# STM32U575 register map
File version: 1.4
CPU: CM33 r0p1, little endian, MPU, FPU, 4 interrupt priority bits
Registers are 32-bit, read-write, reset 0x0 unless marked. A register's access mark holds for its fields unless they carry their own. Offsets are from the block's base; [hi:lo] are bit positions; lines under a group give offsets from that group; {n}, {i} and the like mark numbered series; 'fields as' and 'values as' point back to an identical list.

## ADC1
Base 0x42028000
Same registers: SEC_ADC1 0x52028000
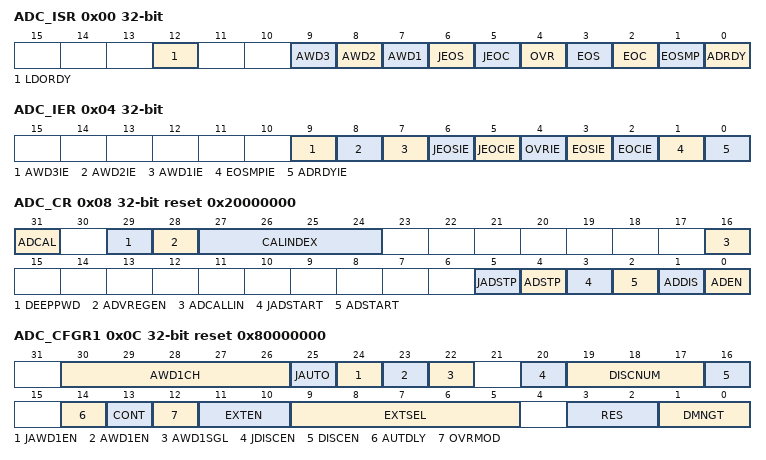
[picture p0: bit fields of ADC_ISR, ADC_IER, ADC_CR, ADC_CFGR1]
0x00 ADC_ISR access per field — ADC interrupt and status register
  [12] LDORDY ro — ADC voltage regulator ready This bit is set by hardware. It indicates that the ADC internal supply is ready. The ADC is available after tADCVREG_SETUP time.
    0=ADC voltage regulator disabled; 1=ADC voltage regulator enabled
  [9] AWD3 rw — Analog watchdog 3 flag This bit is set by hardware when the converted voltage crosses the values programmed in the fields LT3[7:0] and HT3[7:0] of ADC_LTR3 & ADC_HTR3 register. It is cleared by software writing 1 to it.
    0=No analog watchdog 3 event occurred (or the flag event was already acknowledged and cleared by software); 1=Analog watchdog 3 event occurred
  [8] AWD2 rw — Analog watchdog 2 flag This bit is set by hardware when the converted voltage crosses the values programmed in the fields LT2[7:0] and HT2[7:0] of ADC_LTR2 & ADC_HTR2 register. It is cleared by software writing 1 to it.
    0=No analog watchdog 2 event occurred (or the flag event was already acknowledged and cleared by software); 1=Analog watchdog 2 event occurred
  [7] AWD1 rw — Analog watchdog 1 flag This bit is set by hardware when the converted voltage crosses the values programmed in the fields LT1[11:0] and HT1[11:0] of ADC_LTR1, & ADC_HTR1 register. It is cleared by software. writing 1 to it.
    0=No analog watchdog 1 event occurred (or the flag event was already acknowledged and cleared by software); 1=Analog watchdog 1 event occurred
  [6] JEOS rw — Injected channel end of sequence flag This bit is set by hardware at the end of the conversions of all injected channels in the group. It is cleared by software writing 1 to it.
    0=Injected conversion sequence not complete (or the flag event was already acknowledged and cleared by software); 1=Injected conversions complete
  [5] JEOC rw — Injected channel end of conversion flag This bit is set by hardware at the end of each injected conversion of a channel when a new data is available in the corresponding ADC_JDRy register. It is cleared by software writing 1 to it or by reading the corresponding ADC_JDRy register
    0=Injected channel conversion not complete (or the flag event was already acknowledged and cleared by software); 1=Injected channel conversion complete
  [4] OVR rw — ADC overrun This bit is set by hardware when an overrun occurs on a regular channel, meaning that a new conversion has completed while the EOC flag was already set. It is cleared by software writing 1 to it.
    0=No overrun occurred (or the flag event was already acknowledged and cleared by software); 1=Overrun has occurred
  [3] EOS rw — End of regular sequence flag This bit is set by hardware at the end of the conversions of a regular sequence of channels. It is cleared by software writing 1 to it.
    0=Regular Conversions sequence not complete (or the flag event was already acknowledged and cleared by software); 1=Regular Conversions sequence complete
  [2] EOC rw — End of conversion flag This bit is set by hardware at the end of each regular conversion of a channel when a new data is available in the ADC_DR register. It is cleared by software writing 1 to it or by reading the ADC_DR register
    0=Regular channel conversion not complete (or the flag event was already acknowledged and cleared by software); 1=Regular channel conversion complete
  [1] EOSMP rw — End of sampling flag This bit is set by hardware during the conversion of any channel (only for regular channels), at the end of the sampling phase.
    0=not at the end of the sampling phase (or the flag event was already acknowledged and cleared by software); 1=End of sampling phase reached
  [0] ADRDY rw — ADC ready This bit is set by hardware after the ADC has been enabled (bit ADEN = 1) and when the ADC reaches a state where it is ready to accept conversion requests. It is cleared by software writing 1 to it.
    0=ADC not yet ready to start conversion (or the flag event was already acknowledged and cleared by software); 1=ADC is ready to start conversion
0x04 ADC_IER — ADC interrupt enable register
  [9] AWD3IE — Analog watchdog 3 interrupt enable This bit is set and cleared by software to enable/disable the analog watchdog 2 interrupt. Note: Software is allowed to write this bit only when ADSTART = 0 and JADSTART = 0 (which ensures that no conversion is ongoing).
    0=Analog watchdog 3 interrupt disabled; 1=Analog watchdog 3 interrupt enabled
  [8] AWD2IE — Analog watchdog 2 interrupt enable This bit is set and cleared by software to enable/disable the analog watchdog 2 interrupt. Note: Software is allowed to write this bit only when ADSTART = 0 and JADSTART = 0 (which ensures that no conversion is ongoing).
    0=Analog watchdog 2 interrupt disabled; 1=Analog watchdog 2 interrupt enabled
  [7] AWD1IE — Analog watchdog 1 interrupt enable This bit is set and cleared by software to enable/disable the analog watchdog 1 interrupt. Note: Software is allowed to write this bit only when ADSTART = 0 and JADSTART = 0 (which ensures that no conversion is ongoing).
    0=Analog watchdog 1 interrupt disabled; 1=Analog watchdog 1 interrupt enabled
  [6] JEOSIE — End of injected sequence of conversions interrupt enable This bit is set and cleared by software to enable/disable the end of injected sequence of conversions interrupt. Note: Software is allowed to write this bit only when JADSTART = 0 (which ensures that no injected conversion is ongoing).
    0=JEOS interrupt disabled; 1=JEOS interrupt enabled. An interrupt is generated when the JEOS bit is set.
  [5] JEOCIE — End of injected conversion interrupt enable This bit is set and cleared by software to enable/disable the end of an injected conversion interrupt. Note: Software is allowed to write this bit only when JADSTART = 0 (which ensures that no regular conversion is ongoing).
    0=JEOC interrupt disabled; 1=JEOC interrupt enabled. An interrupt is generated when the JEOC bit is set.
  [4] OVRIE — Overrun interrupt enable This bit is set and cleared by software to enable/disable the Overrun interrupt of a regular conversion. Note: Software is allowed to write this bit only when ADSTART = 0 (which ensures that no regular conversion is ongoing).
    0=Overrun interrupt disabled; 1=Overrun interrupt enabled. An interrupt is generated when the OVR bit is set.
  [3] EOSIE — End of regular sequence of conversions interrupt enable This bit is set and cleared by software to enable/disable the end of regular sequence of conversions interrupt. Note: Software is allowed to write this bit only when ADSTART = 0 (which ensures that no regular conversion is ongoing).
    0=EOS interrupt disabled; 1=EOS interrupt enabled. An interrupt is generated when the EOS bit is set.
  [2] EOCIE — End of regular conversion interrupt enable This bit is set and cleared by software to enable/disable the end of a regular conversion interrupt. Note: Software is allowed to write this bit only when ADSTART = 0 (which ensures that no regular conversion is ongoing).
    0=EOC interrupt disabled; 1=EOC interrupt enabled. An interrupt is generated when the EOC bit is set.
  [1] EOSMPIE — End of sampling flag interrupt enable for regular conversions This bit is set and cleared by software to enable/disable the end of the sampling phase interrupt for regular conversions. Note: Software is allowed to write this bit only when ADSTART = 0 (which ensures that no regular conversion is ongoing).
    0=EOSMP interrupt disabled; 1=EOSMP interrupt enabled. An interrupt is generated when the EOSMP bit is set.
  [0] ADRDYIE — ADC ready interrupt enable This bit is set and cleared by software to enable/disable the ADC Ready interrupt. Note: Software is allowed to write this bit only when ADSTART = 0 and JADSTART = 0 (which ensures that no conversion is ongoing).
    0=ADRDY interrupt disabled; 1=ADRDY interrupt enabled. An interrupt is generated when the ADRDY bit is set.
0x08 ADC_CR reset 0x20000000 — ADC control register
  [31] ADCAL — ADC calibration This bit is set by software to start the ADC calibration. It is cleared by hardware after calibration is complete. Note: The software is allowed to launch a calibration by setting ADCAL only when ADEN = 0.
    0=Calibration complete; 1=Write 1 to calibrate the ADC. Read at 1 means that a calibration in progress.
  [29] DEEPPWD — Deep-power-down enable This bit is set and cleared by software to put the ADC in Deep-power-down mode. Note: The software is allowed to write this bit only when the ADC is disabled (ADCAL = 0, JADSTART = 0, JADSTP = 0, ADSTART = 0, ADSTP = 0, ADDIS = 0 and ADEN = 0).
    0=ADC not in deep-power down; 1=ADC in Deep-power-down (default reset state)
  [28] ADVREGEN — ADC voltage regulator enable This bits is set by software to enable the ADC voltage regulator. Before performing any operation such as launching a calibration or enabling the ADC, the ADC voltage regulator must first be enabled and the software must wait for the regulator start-up time. For more details about the ADC voltage regulator enable and disable sequences, refer to (ADVREGEN). The software can program this bit field only when the ADC is disabled (ADCAL = 0, JADSTART = 0, ADSTART = 0, ADSTP = 0, ADDIS = 0 and ADEN = 0).
    0=ADC Voltage regulator disabled; 1=ADC Voltage regulator enabled
  [27:24] CALINDEX — Calibration factor This bitfield controls the calibration factor to be read or written. Calibration index 0 is dedicated to single-ended and differential offsets, calibration index 1 to 7 to the linearity calibration factors, and index 8 to the internal offset: Others: Reserved, must not be used Note: ADC_CALFACT2[31:0] correspond to the location of CALINDEX[3:0] calibration factor data (see for details).
    0=Offset calibration factor; {v}=linearity calibration factor {v} (v=1..6); 7=linearity calibration factor 7 and internal offset (write access only); 8=internal offset (read access only)
  [16] ADCALLIN — Linearity calibration This bit is set and cleared by software to enable the linearity calibration. Note: The software is allowed to write this bit only when the ADC is disabled and is not calibrating (ADCAL = 0, JADSTART = 0, JADSTP = 0, ADSTART = 0, ADSTP = 0, ADDIS = 0 and ADEN = 0).
    0=Writing ADCAL launches a calibration without the linearity calibration; 1=Writing ADCAL launches a calibration with he linearity calibration
  [5] JADSTP — ADC stop of injected conversion command This bit is set by software to stop and discard an ongoing injected conversion (JADSTP Command). It is cleared by hardware when the conversion is effectively discarded and the ADC injected sequence and triggers can be re-configured. The ADC is then ready to accept a new start of injected conversions (JADSTART command). Note: The software is allowed to set JADSTP only when JADSTART = 1 and ADDIS = 0 (ADC is enabled and eventually converting an injected conversion and there is no pending request to disable the ADC). In Auto-injection mode (JAUTO = 1), setting ADSTP bit aborts both regular and injected conversions (do not use JADSTP)
    0=No ADC stop injected conversion command ongoing; 1=Write 1 to stop injected conversions ongoing. Read 1 means that an ADSTP command is in progress.
  [4] ADSTP — ADC stop of regular conversion command This bit is set by software to stop and discard an ongoing regular conversion (ADSTP Command). It is cleared by hardware when the conversion is effectively discarded and the ADC regular sequence and triggers can be re-configured. The ADC is then ready to accept a new start of regular conversions (ADSTART command). Note: The software is allowed to set ADSTP only when ADSTART = 1 and ADDIS = 0 (ADC is enabled and eventually converting a regular conversion and there is no pending request to disable the ADC). In Auto-injection mode (JAUTO = 1), setting ADSTP bit aborts both regular and injected conversions (do not use JADSTP).
    0=No ADC stop regular conversion command ongoing; 1=Write 1 to stop regular conversions ongoing. Read 1 means that an ADSTP command is in progress.
  [3] JADSTART — ADC start of injected conversion This bit is set by software to start ADC conversion of injected channels. Depending on the configuration bits JEXTEN[1:0], a conversion starts immediately (software trigger configuration) or once an injected hardware trigger event occurs (hardware trigger configuration). It is cleared by hardware: in Single conversion mode when software trigger is selected (JEXTSEL = 0x0): at the assertion of the end of injected conversion sequence (JEOS) flag. in all cases: after the execution of the JADSTP command, at the same time as JADSTP is cleared by hardware. Note: The software is allowed to set JADSTART only when ADEN = 1 and ADDIS = 0 (ADC is enabled and there is no pending request to disable the ADC). In Auto-injection mode (JAUTO = 1), regular and auto-injected conversions are started by setting bit ADSTART (JADSTART must be kept cleared)
    0=No ADC injected conversion is ongoing; 1=Write 1 to start injected conversions. Read 1 means that the ADC is operating and eventually converting an injected channel.
  [2] ADSTART — ADC start of regular conversion This bit is set by software to start ADC conversion of regular channels. Depending on the configuration bits EXTEN[1:0], a conversion starts immediately (software trigger configuration) or once a regular hardware trigger event occurs (hardware trigger configuration). It is cleared by hardware: in Single conversion mode (CONT = 0, DISCEN = 0) when software trigger is selected (EXTEN[1:0] = 0x0): at the assertion of the end of regular conversion sequence (EOS) flag. In Discontinuous conversion mode (CONT = 0, DISCEN = 1), when the software trigger is selected (EXTEN[1:0] = 0x0): at the end of conversion (EOC) flag. in all other cases: after the execution of the ADSTP command, at the same time that ADSTP is cleared by hardware. Note: The software is allowed to set ADSTART only when ADEN = 1 and ADDIS = 0 (ADC is enabled and there is no pending request to disable the ADC) In Auto-injection mode (JAUTO = 1), regular and auto-injected conversions are started by setting bit ADSTART (JADSTART must be kept cleared)
    0=No ADC regular conversion is ongoing; 1=Write 1 to start regular conversions. Read 1 means that the ADC is operating and eventually converting a regular channel.
  [1] ADDIS — ADC disable command This bit is set by software to disable the ADC (ADDIS command) and put it into power-down state (OFF state). It is cleared by hardware once the ADC is effectively disabled (ADEN is also cleared by hardware at this time). Note: The software is allowed to set ADDIS only when ADEN = 1 and both ADSTART = 0 and JADSTART = 0 (which ensures that no conversion is ongoing)
    0=no ADDIS command ongoing; 1=Write 1 to disable the ADC. Read 1 means that an ADDIS command is in progress.
  [0] ADEN — ADC enable control This bit is set by software to enable the ADC. The ADC is effectively ready to operate once the flag ADRDY has been set. It is cleared by hardware when the ADC is disabled, after the execution of the ADDIS command. Note: The software is allowed to set ADEN only when all bits of ADC_CR registers are 0 (ADCAL = 0, JADSTART = 0, ADSTART = 0, ADSTP = 0, ADDIS = 0 and ADEN = 0) except for bit ADVREGEN which must be 1 (and the software must have wait for the startup time of the voltage regulator)
    0=ADC is disabled (OFF state); 1=Write 1 to enable the ADC
0x0C ADC_CFGR1 reset 0x80000000 — ADC configuration register
  [30:26] AWD1CH — Analog watchdog 1 channel selection These bits are set and cleared by software. They select the input channel to be guarded by the analog watchdog. ..... Others: Reserved, must not be used Note: The channel selected by AWD1CH must be also selected into the SQRi or JSQRi registers. Software is allowed to write these bits only when ADSTART = 0 and JADSTART = 0 (which ensures that no conversion is ongoing).
    0=ADC analog input channel-0 monitored by AWD1; 1=ADC analog input channel-1 monitored by AWD1; 19=ADC analog input channel-19 monitored by AWD1
  [25] JAUTO — Automatic injected group conversion This bit is set and cleared by software to enable/disable automatic injected group conversion after regular group conversion. Note: The software is allowed to write this bit only when ADSTART = 0 and JADSTART = 0 (which ensures that no regular nor injected conversion is ongoing).
    0=Automatic injected group conversion disabled; 1=Automatic injected group conversion enabled
  [24] JAWD1EN — Analog watchdog 1 enable on injected channels This bit is set and cleared by software Note: The software is allowed to write this bit only when JADSTART = 0 (which ensures that no injected conversion is ongoing).
    0=Analog watchdog 1 disabled on injected channels; 1=Analog watchdog 1 enabled on injected channels
  [23] AWD1EN — Analog watchdog 1 enable on regular channels This bit is set and cleared by software Note: The software is allowed to write this bit only when ADSTART = 0 (which ensures that no regular conversion is ongoing).
    0=Analog watchdog 1 disabled on regular channels; 1=Analog watchdog 1 enabled on regular channels
  [22] AWD1SGL — Enable the watchdog 1 on a single channel or on all channels This bit is set and cleared by software to enable the analog watchdog on the channel identified by the AWD1CH[4:0] bits or on all the channels Note: The software is allowed to write these bits only when ADSTART = 0 and JADSTART = 0 (which ensures that no conversion is ongoing).
    0=Analog watchdog 1 enabled on all channels; 1=Analog watchdog 1 enabled on a single channel
  [20] JDISCEN — Discontinuous mode on injected channels This bit is set and cleared by software to enable/disable discontinuous mode on the injected channels of a group. Note: The software is allowed to write this bit only when JADSTART = 0 (which ensures that no injected conversion is ongoing). It is not possible to use both auto-injected mode and discontinuous mode simultaneously: the bits DISCEN and JDISCEN must be kept cleared by software when JAUTO is set.
    0=Discontinuous mode on injected channels disabled; 1=Discontinuous mode on injected channels enabled
  [19:17] DISCNUM — Discontinuous mode channel count These bits are written by software to define the number of regular channels to be converted in discontinuous mode, after receiving an external trigger. ... Note: The software is allowed to write these bits only when ADSTART = 0 (which ensures that no regular conversion is ongoing).
    0=1 channel; 1=2 channels; 7=8 channels
  [16] DISCEN — Discontinuous mode for regular channels This bit is set and cleared by software to enable/disable Discontinuous mode for regular channels. Note: It is not possible to have both discontinuous mode and continuous mode enabled: it is forbidden to set both DISCEN = 1 and CONT = 1. It is not possible to use both auto-injected mode and discontinuous mode simultaneously: the bits DISCEN and JDISCEN must be kept cleared by software when JAUTO is set. The software is allowed to write this bit only when ADSTART = 0 (which ensures that no regular conversion is ongoing).
    0=Discontinuous mode for regular channels disabled; 1=Discontinuous mode for regular channels enabled
  [14] AUTDLY — Delayed conversion mode This bit is set and cleared by software to enable/disable the Auto Delayed Conversion mode.. Note: The software is allowed to write this bit only when ADSTART = 0 and JADSTART = 0 (which ensures that no conversion is ongoing).
    0=Auto-delayed conversion mode off; 1=Auto-delayed conversion mode on
  [13] CONT — Single / continuous conversion mode for regular conversions This bit is set and cleared by software. If it is set, regular conversion takes place continuously until it is cleared. Note: It is not possible to have both discontinuous mode and continuous mode enabled: it is forbidden to set both DISCEN = 1 and CONT = 1. The software is allowed to write this bit only when ADSTART = 0 (which ensures that no regular conversion is ongoing).
    0=Single conversion mode; 1=Continuous conversion mode
  [12] OVRMOD — Overrun Mode This bit is set and cleared by software and configure the way data overrun is managed. Note: The software is allowed to write this bit only when ADSTART = 0 (which ensures that no regular conversion is ongoing).
    0=ADC_DR register is preserved with the old data when an overrun is detected; 1=ADC_DR register is overwritten with the last conversion result when an overrun is detected
  [11:10] EXTEN — External trigger enable and polarity selection for regular channels These bits are set and cleared by software to select the external trigger polarity and enable the trigger of a regular group. Note: The software is allowed to write these bits only when ADSTART = 0 (which ensures that no regular conversion is ongoing).
    0=Hardware trigger detection disabled (conversions can be launched by software); 1=Hardware trigger detection on the rising edge; 2=Hardware trigger detection on the falling edge; 3=Hardware trigger detection on both the rising and falling edges
  [9:5] EXTSEL — External trigger selection for regular group These bits select the external event used to trigger the start of conversion of a regular group: ... Refer to the ADC external trigger for regular channels in signals for details on trigger mapping. Note: The software is allowed to write these bits only when ADSTART = 0 (which ensures that no regular conversion is ongoing).
    0=adc_ext_trg0; 1=adc_ext_trg1
  [3:2] RES — Data resolution These bits are written by software to select the resolution of the conversion. Note: The software is allowed to write these bits only when ADSTART = 0 and JADSTART = 0 (which ensures that no conversion is ongoing).
    0=14 bits; 1=12 bits; 2=10 bits; 3=8bits
  [1:0] DMNGT — Data management configuration This bit is set and cleared by software to select how the ADC interface output data are managed. Note: The software is allowed to write this bit only when ADSTART = 0 and JADSTART = 0 (which ensures that no conversion is ongoing).
    0=Regular conversion data stored in DR only; 1=DMA One -shot mode selected; 2=MDF mode selected; 3=DMA Circular mode selected
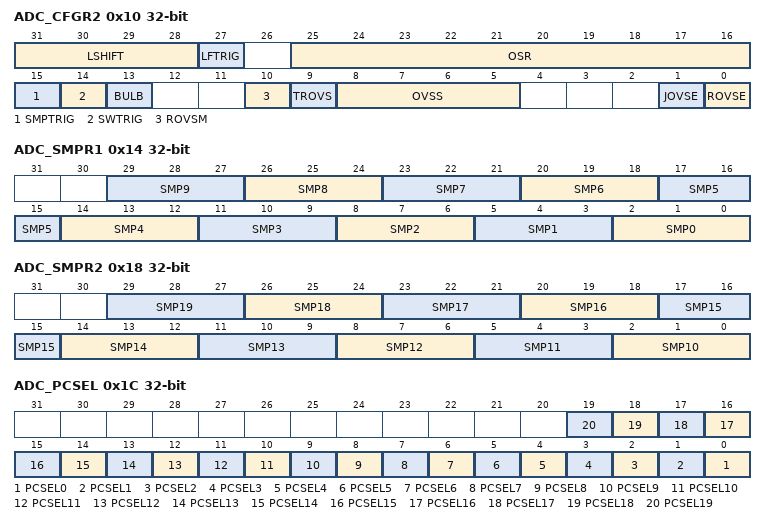
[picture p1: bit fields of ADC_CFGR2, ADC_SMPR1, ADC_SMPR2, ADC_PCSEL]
0x10 ADC_CFGR2 — ADC configuration register 2
  [31:28] LSHIFT — Left shift factor This bitfield is set and cleared by software to define the left shifting applied to the final result with or without oversampling. Note: The software is allowed to write this bit only when ADSTART = 0 (which ensures that no conversion is ongoing).
    0=No left shift; {v}={v}-bit left shift (v=1..15)
  [27] LFTRIG — Low-frequency trigger This bit is set and cleared by software Note: The software is allowed to write this bit only when ADSTART = 0 (which ensures that no conversion is ongoing).
    0=Low-frequency trigger mode disabled; 1=Low-frequency trigger mode enabled
  [25:16] OSR — Oversampling ratio This bitfield is set and cleared by software to define the oversampling ratio. 2: 3x ... 1023: 1024x Note: The software is allowed to write this bit only when ADSTART = 0 (which ensures that no conversion is ongoing).
    0=1x (no oversampling); 1=2x
  [15] SMPTRIG — Sampling time control trigger mode This bit is set and cleared by software to enable the sampling time control trigger mode. The sampling time starts on the trigger rising edge, and the conversion on the trigger falling edge. EXTEN[1:0] bits must be set to 01. BULB bit must not be set when the SMPTRIG bit is set. When EXTEN[1:0] bits is set to 00, set SWTRIG to start the sampling and clear SWTRIG bit to start the conversion. Note: The software is allowed to write this bit only when ADSTART = 0 (which ensures that no conversion is ongoing).
    0=Sampling time control trigger mode disabled; 1=Sampling time control trigger mode enabled
  [14] SWTRIG — Software trigger bit for sampling time control trigger mode This bit is set and cleared by software to enable the bulb sampling mode. Note: The software is allowed to write this bit only when ADSTART = 0 (which ensures that no conversion is ongoing).
    0=Software trigger starts the conversion for sampling time control trigger mode; 1=Software trigger starts the sampling for sampling time control trigger mode
  [13] BULB — Bulb sampling mode This bit is set and cleared by software to select the bulb sampling mode. SMPTRIG bit must not be set when the BULB bit is set. The very first ADC conversion is performed with the sampling time specified in SMPx bits. Note: The software is allowed to write this bit only when ADSTART = 0 (which ensures that no conversion is ongoing).
    0=Bulb sampling mode disabled; 1=Bulb sampling mode enabled. The sampling period starts just after the previous end of the conversion.
  [10] ROVSM — Regular Oversampling mode This bit is set and cleared by software to select the regular oversampling mode. Note: The software is allowed to write this bit only when ADSTART = 0 (which ensures that no conversion is ongoing).
    0=Continued mode: When injected conversions are triggered, the oversampling is temporary stopped and continued after the injection sequence (oversampling buffer is maintained during injected sequence); 1=Resumed mode: When injected conversions are triggered, the current oversampling is aborted and resumed from start after the injection sequence (oversampling buffer is zeroed by injected sequence start)
  [9] TROVS — Triggered Regular Oversampling This bit is set and cleared by software to enable triggered oversampling Note: The software is allowed to write this bit only when ADSTART = 0 (which ensures that no conversion is ongoing).
    0=All oversampled conversions for a channel are done consecutively following a trigger; 1=Each oversampled conversion for a channel needs a new trigger
  [8:5] OVSS — Oversampling right shift This bit field is set and cleared by software to define the right shifting applied to the raw oversampling result. Others: Reserved, must not be used. Note: The software is allowed to write these bits only when ADSTART = 0 (which ensures that no conversion is ongoing).
    0=No right shift; {v}={v}-bit right shift (v=1..11)
  [1] JOVSE — Injected Oversampling Enable This bit is set and cleared by software to enable injected oversampling. Note: The software is allowed to write this bit only when ADSTART = 0 and JADSTART = 0 (which ensures that no conversion is ongoing)
    0=Injected oversampling disabled; 1=Injected oversampling enabled
  [0] ROVSE — Regular Oversampling Enable This bit is set and cleared by software to enable regular oversampling. Note: The software is allowed to write this bit only when ADSTART = 0 and JADSTART = 0 (which ensures that no conversion is ongoing)
    0=Regular Oversampling disabled; 1=Regular Oversampling enabled
0x14 ADC_SMPR1 — ADC sample time register 1
  [all] fields
    0=5 ADC clock cycles; 1=6 ADC clock cycles; 2=12 ADC clock cycles; 3=20 ADC clock cycles; 4=36 ADC clock cycles; 5=68 ADC clock cycles; 6=391 ADC clock cycles; 7=814 ADC clock cycles
  [3n+2:3n] SMP{n} (n=0..9) — Channel x sampling time selection (x = 0 to 9) These bits are written by software to select the sampling time individually for each channel. During sample cycles, the channel selection bits must remain unchanged. Note: The software is allowed to write these bits only when ADSTART = 0 and JADSTART = 0 (which ensures that no conversion is ongoing).
0x18 ADC_SMPR2 — ADC sample time register 2
  [all] fields
    values as the fields of ADC_SMPR1
  [3n-28:3n-30] SMP{n} (n=10..19) — Channel x sampling time selection (x = 0 to 9) These bits are written by software to select the sampling time individually for each channel. During sampling cycles, the channel selection bits must remain unchanged. Note: The software is allowed to write these bits only when ADSTART = 0 and JADSTART = 0 (which ensures that no conversion is ongoing).
0x1C ADC_PCSEL — ADC channel preselection register
  [all] fields
    0=Input channel i (VINP[i]) is not preselected for conversion, the ADC conversion of this channel shows a wrong result; 1=Input channel i (VINP[i]) is preselected for conversion
  [n] PCSEL{n} (n=0..19) — Channel i (VINP[i]) preselection These bits are written by software to preselect the input channel I/O instance to be converted. Note: The software is allowed to write these bits only when ADSTART = 0 and JADSTART = 0 (which ensures that no conversion is ongoing).
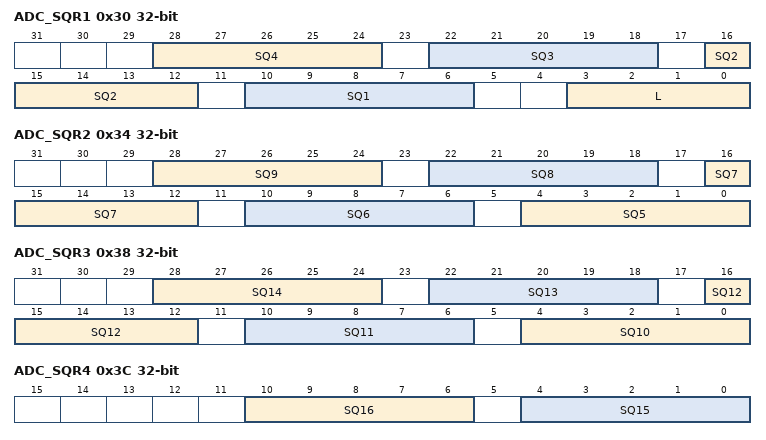
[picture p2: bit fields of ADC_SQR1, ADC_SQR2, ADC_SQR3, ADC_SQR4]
0x30 ADC_SQR1 — ADC regular sequence register 1
  [28:24] SQ4 — 4th conversion in regular sequence These bits are written by software with the channel number (0..19) assigned as the 4th in the regular conversion sequence.
  [22:18] SQ3 — 3rd conversion in regular sequence These bits are written by software with the channel number (0..19) assigned as the 3rd in the regular conversion sequence. Note: The software is allowed to write these bits only when ADSTART = 0 (which ensures that no regular conversion is ongoing).
  [16:12] SQ2 — 2nd conversion in regular sequence These bits are written by software with the channel number (0..19) assigned as the 2nd in the regular conversion sequence. Note: The software is allowed to write these bits only when ADSTART = 0 (which ensures that no regular conversion is ongoing).
  [10:6] SQ1 — 1st conversion in regular sequence These bits are written by software with the channel number (0..19) assigned as the 1st in the regular conversion sequence. Note: The software is allowed to write these bits only when ADSTART = 0 (which ensures that no regular conversion is ongoing).
  [3:0] L — Regular channel sequence length These bits are written by software to define the total number of conversions in the regular channel conversion sequence. ... Note: The software is allowed to write these bits only when ADSTART = 0 (which ensures that no regular conversion is ongoing).
    0=1 conversion; 1=2 conversions; 15=16 conversions
0x34 ADC_SQR2 — ADC regular sequence register 2
  [28:24] SQ9 — 9th conversion in regular sequence These bits are written by software with the channel number (0..19) assigned as the 9th in the regular conversion sequence. Note: The software is allowed to write these bits only when ADSTART = 0 (which ensures that no regular conversion is ongoing).
  [22:18] SQ8 — 8th conversion in regular sequence These bits are written by software with the channel number (0..19) assigned as the 8th in the regular conversion sequence Note: The software is allowed to write these bits only when ADSTART = 0 (which ensures that no regular conversion is ongoing).
  [16:12] SQ7 — 7th conversion in regular sequence These bits are written by software with the channel number (0..19) assigned as the 7th in the regular conversion sequence. Note: The software is allowed to write these bits only when ADSTART = 0 (which ensures that no regular conversion is ongoing).
  [10:6] SQ6 — 6th conversion in regular sequence These bits are written by software with the channel number (0..19) assigned as the 6th in the regular conversion sequence. Note: The software is allowed to write these bits only when ADSTART = 0 (which ensures that no regular conversion is ongoing).
  [4:0] SQ5 — 5th conversion in regular sequence These bits are written by software with the channel number (0..19) assigned as the 5th in the regular conversion sequence. Note: The software is allowed to write these bits only when ADSTART = 0 (which ensures that no regular conversion is ongoing).
0x38 ADC_SQR3 — ADC regular sequence register 3
  [6n-56:6n-60] SQ{n} (n=10..14) — {n}th conversion in regular sequence These bits are written by software with the channel number (0..19) assigned as the {n}th in the regular conversion sequence. Note: The software is allowed to write these bits only when ADSTART = 0 (which ensures that no regular conversion is ongoing).
0x3C ADC_SQR4 — ADC regular sequence register 4
  [10:6] SQ16 — 16th conversion in regular sequence These bits are written by software with the channel number (0..19) assigned as the 16th in the regular conversion sequence. Note: The software is allowed to write these bits only when ADSTART = 0 (which ensures that no regular conversion is ongoing).
  [4:0] SQ15 — 15th conversion in regular sequence These bits are written by software with the channel number (0..19) assigned as the 15th in the regular conversion sequence. Note: The software is allowed to write these bits only when ADSTART = 0 (which ensures that no regular conversion is ongoing).
0x40 ADC_DR ro — ADC regular Data Register
  [31:0] RDATA — Regular data converted These bits are read-only. They contain the conversion result from the last converted regular channel. The data are left- or right-aligned as described in .
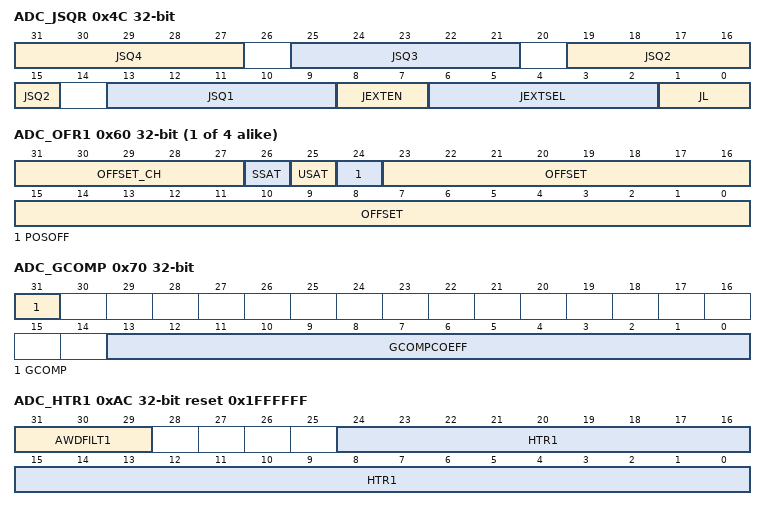
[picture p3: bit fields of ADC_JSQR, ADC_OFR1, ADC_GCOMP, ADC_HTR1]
0x4C ADC_JSQR — ADC injected sequence register
  [31:27] JSQ4 — 4th conversion in the injected sequence These bits are written by software with the channel number (0..19) assigned as the 4th in the injected conversion sequence. Note: The software is allowed to write these bits only when JADSTART = 0 (which ensures that no injected conversion is ongoing.
  [25:21] JSQ3 — 3rd conversion in the injected sequence These bits are written by software with the channel number (0..19) assigned as the 3rd in the injected conversion sequence. Note: The software is allowed to write these bits only when JADSTART = 0 (which ensures that no injected conversion is ongoing.
  [19:15] JSQ2 — 2nd conversion in the injected sequence These bits are written by software with the channel number (0..19) assigned as the 2nd in the injected conversion sequence. Note: The software is allowed to write these bits only when JADSTART = 0 (which ensures that no injected conversion is ongoing.
  [13:9] JSQ1 — 1st conversion in the injected sequence These bits are written by software with the channel number (0..19) assigned as the 1st in the injected conversion sequence. Note: The software is allowed to write these bits only when JADSTART = 0 (which ensures that no injected conversion is ongoing.
  [8:7] JEXTEN — External trigger enable and polarity selection for injected channels These bits are set and cleared by software to select the external trigger polarity and enable the trigger of an injected group. Note: The software is allowed to write these bits only when JADSTART = 0 (which ensures that no injected conversion is ongoing.
    values as ADC_CFGR1.EXTEN
  [6:2] JEXTSEL — External trigger selection for injected group These bits select the external event used to trigger the start of conversion of an injected group: ... Refer to the ADC external trigger for injected channels in internal signals for details on trigger mapping. Note: The software is allowed to write these bits only when JADSTART = 0 (which ensures that no injected conversion is ongoing.
    0=adc_jext_trg0; 1=adc_jext_trg1
  [1:0] JL — Injected channel sequence length These bits are written by software to define the total number of conversions in the injected channel conversion sequence. Note: The software is allowed to write these bits only when JADSTART = 0 (which ensures that no injected conversion is ongoing.
    0=1 conversion; 1=2 conversions; 2=3 conversions; 3=4 conversions
{0x5C+4i} ADC_OFR{i} (i=1..4) — ADC offset register
  [31:27] OFFSET_CH — Channel selection for the data offset y These bits are written by software to define the channel to which the offset programmed into OFFSETy[25:0] bits applies. Note: The software is allowed to write these bits only when ADSTART = 0 and JADSTART = 0 (which ensures that no conversion is ongoing). If OFFSETy_EN bit is set, it is not allowed to select the same channel in different ADC_OFRy registers.
  [26] SSAT — Signed saturation enable This bit is written by software to enable or disable the Signed saturation feature. (see OFFSETy_CH, OVSS, LSHIFT, USAT, SSAT) for details). Note: The software is allowed to write this bit only when ADSTART = 0 and JADSTART = 0 (which ensures that no conversion is ongoing).
    0=Offset is subtracted maintaining data integrity and extending converted data size (9-bit and 15-bit signed format); 1=Offset is subtracted and result is saturated to maintain converted data size
  [25] USAT — Unsigned saturation enable This bit is written by software to enable or disable the unsigned saturation feature. Note: The software is allowed to write this bit only when ADSTART = 0 and JADSTART = 0 (which ensures that no conversion is ongoing).
    0=Offset is subtracted maintaining data integrity and keeping converted data size; 1=Offset is subtracted and result is saturated to maintain converted data size
  [24] POSOFF — offset sign This bit is set and cleared by software to enable the positive offset. Note: The software is allowed to write these bits only when ADSTART = 0 and JADSTART = 0 (which ensures that no conversion is ongoing).
    0=Negative offset; 1=Positive offset
  [23:0] OFFSET — Data offset y for the channel programmed into OFFSETy_CH[4:0] bits These bits are written by software to define the offset y to be subtracted from the raw converted data when converting a channel (regular or injected). The channel to which the data offset y applies must be programmed to the OFFSETy_CH[4:0] bits. The conversion result can be read from in the ADC_DR (regular conversion) or from in the ADC_JDRyi registers (injected conversion). When OFFSETy[21:0] bitfield is reset, the offset compensation is disabled. Note: The software is allowed to write these bits only when ADSTART = 0 and JADSTART = 0 (which ensures that no conversion is ongoing). If several offsets (OFFSETy) point to the same channel, only the offset with the lowest y value is considered for the subtraction. For example, if OFFSET1_CH[4:0] = 4 and OFFSET2_CH[4:0] = 4, this is OFFSET1[25:0] that is subtracted when converting channel 4.
0x70 ADC_GCOMP — ADC gain compensation register
  [31] GCOMP — Gain compensation mode This bit is set and cleared by software to enable the gain compensation mode. Note: The software is allowed to write this bit only when ADSTART = 0 (which ensures that no conversion is ongoing).
    0=Regular ADC operating mode; 1=Gain compensation enabled and applied on all channels
  [13:0] GCOMPCOEFF — Gain compensation coefficient These bits are set and cleared by software to program the gain compensation coefficient. ... ... The coefficient is divided by 4096 to get the gain factor ranging from 0 to 3.999756. Note: This gain compensation is only applied when GCOMP bit of ADCx_CFGR2 register is 1.
    0x800=gain factor of 0.5; 0x1000=gain factor of 1; 0x2000=gain factor of 2; 0x3000=gain factor of 3
{0x7C+4i} ADC_JDR{i} ro (i=1..4) — ADC injected data register
  [31:0] JDATA — Injected data These bits are read-only. They contain the conversion result from injected channel y. The data are left -or right-aligned as described in .
0xA0 ADC_AWD2CR — ADC analog watchdog 2 configuration register
  [19:0] AWD2CH — Analog watchdog 2 channel selection These bits are set and cleared by software. They enable and select the input channels to be guarded by the analog watchdog 2. AWD2CH[i] = 0: ADC analog input channel-i is not monitored by AWD2 AWD2CH[i] = 1: ADC analog input channel-i is monitored by AWD2 When AWD2CH[19:0] = 000..0, the analog Watchdog 2 is disabled Note: The channels selected by AWD2CH must be also selected into the SQRi or JSQRi registers. Software is allowed to write these bits only when ADSTART = 0 and JADSTART = 0 (which ensures that no conversion is ongoing).
0xA4 ADC_AWD3CR — ADC analog watchdog 3 configuration register
  [19:0] AWD3CH — Analog watchdog 3 channel selection These bits are set and cleared by software. They enable and select the input channels to be guarded by the analog watchdog 3. AWD3CH[i] = 0: ADC analog input channel-i is not monitored by AWD3 AWD3CH[i] = 1: ADC analog input channel-i is monitored by AWD3 When AWD3CH[19:0] = 000..0, the analog Watchdog 3 is disabled Note: The channels selected by AWD3CH must be also selected into the SQRi or JSQRi registers. The software is allowed to write these bits only when ADSTART = 0 and JADSTART = 0 (which ensures that no conversion is ongoing).
0xA8 ADC_LTR1 — ADC watchdog threshold register 1
  [24:0] LTR1 — Analog watchdog 1 lower threshold These bits are written by software to define the lower threshold for the analog watchdog 1. Refer to AWD2CH, AWD3CH, AWD_HTRy, AWD_LTRy, AWDy).
0xAC ADC_HTR1 reset 0x1FFFFFF — ADC watchdog threshold register 1
  [31:29] AWDFILT1 — Analog watchdog filtering parameter This bit is set and cleared by software. ... Note: The software is allowed to write this bit only when ADSTART = 0 and JADSTART = 0 (which ensures that no conversion is ongoing).
    0=No filtering; 1=two consecutive detection generates an AWDx flag or an interrupt; 7=Eight consecutive detection generates an AWDx flag or an interrupt
  [24:0] HTR1 — Analog watchdog 1 higher threshold These bits are written by software to define the higher threshold for the analog watchdog 1. Refer to AWD2CH, AWD3CH, AWD_HTRy, AWD_LTRy, AWDy).
0xB0 ADC_LTR2 — ADC watchdog lower threshold register 2
  [24:0] LTR2 — Analog watchdog 2 lower threshold These bits are written by software to define the lower threshold for the analog watchdog 2. Refer to AWD2CH, AWD3CH, AWD_HTRy, AWD_LTRy, AWDy).
0xB4 ADC_HTR2 reset 0x1FFFFFF — ADC watchdog higher threshold register 2
  [24:0] HTR2 — Analog watchdog 2 higher threshold These bits are written by software to define the higher threshold for the analog watchdog 2. Refer to AWD2CH, AWD3CH, AWD_HTRy, AWD_LTRy, AWDy).
0xB8 ADC_LTR3 — ADC watchdog lower threshold register 3
  [24:0] LTR3 — Analog watchdog 3 lower threshold These bits are written by software to define the lower threshold for the analog watchdog 3. Refer to AWD2CH, AWD3CH, AWD_HTRy, AWD_LTRy, AWDy).
0xBC ADC_HTR3 reset 0x1FFFFFF — ADC watchdog higher threshold register 3
  [24:0] HTR3 — Analog watchdog 3 higher threshold These bits are written by software to define the higher threshold for the analog watchdog 3. Refer to AWD2CH, AWD3CH, AWD_HTRy, AWD_LTRy, AWDy).
0xC0 ADC_DIFSEL — ADC differential mode selection register
  [19:0] DIFSEL — Differential mode for channels 19 to 0 These bits are set and cleared by software. They allow selecting if a channel is configured as single ended or differential mode. DIFSEL[i] = 0: ADC analog input channel-i is configured in single ended mode DIFSEL[i] = 1: ADC analog input channel-i is configured in differential mode Note: The software is allowed to write these bits only when the ADC is disabled (ADCAL = 0, JADSTART = 0, JADSTP = 0, ADSTART = 0, ADSTP = 0, ADDIS = 0 and ADEN = 0).
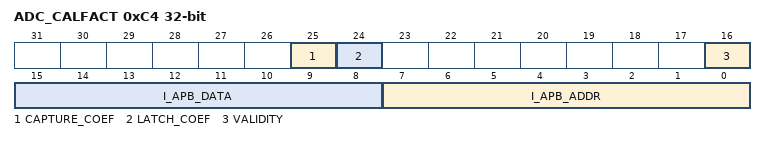
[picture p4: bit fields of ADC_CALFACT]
0xC4 ADC_CALFACT access per field — ADC user control register
  [25] CAPTURE_COEF rw — Calibration factor capture enable bit This bit enables the internal calibration factor capture.
    0=Calibration factor not captured; 1=Calibration factor available in CALFACT[31:0] bits, the calibration factor index being defined by CALINDEX[3:0] bits
  [24] LATCH_COEF rw — Calibration factor latch enable bit This bit latches the calibration factor in the CALFACT[31:0] bits.
    0=No effect; 1=Calibration factor latched in the analog block on LATCH_COEF bit transition from 0 to 1. Prior to latching the calibration factor, CALFACT[31:0] bits must be programmed with the content of CALINDEX[3:0] bits.
  [16] VALIDITY ro — Delayed write access status bit This bit indicates the communication status between the ADC digital and analog blocks.
    0=Operation still in progress; 1=Operation complete
  [15:8] I_APB_DATA ro — Delayed write access data This bitfield contains the data that are being written during delayed write accesses.
  [7:0] I_APB_ADDR ro — Delayed write access address This bitfield contains the address that is being written during delayed write accesses.
0xC8 ADC_CALFACT2 — ADC calibration factor register
  [31:0] CALFACT — Linearity or offset calibration factor These bits can be written either by hardware or by software. They contain the 32-bit offset or linearity calibration factor. When CAPTURE_COEF is set to 1, the calibration factor of the analog block is read back and stored in CALFACT[31:0], indexed by CALINDEX[3:0] bits. When LATCH_COEF is set to 1, the calibration factor of the analog block is updated with the value programmed in CALFACT[31:0], indexed by CALINDEX[3:0] bits. To read all calibration factors, perform nine accesses to the ADC_CALFACT2 register. To write all calibration factors, perform eight accesses to the ADC_CALFACT2 register. Note: The software is allowed to write these bits only when ADEN = 1, ADSTART = 0 and JADSTART = 0 (ADC is enabled and no calibration is ongoing and no conversion is ongoing).
